# MCU_R5FSS0_CORE0 register map
Vendor: Texas Instruments
Peripheral module from a debugger description file (folder J7ES).
Registers are 32-bit, read-write, reset 0x0 unless marked. A register's access mark holds for its fields unless they carry their own. Offsets are as the file gives them; lines under a group give offsets from that group; [hi:lo] are bit positions; {n}, {i} and the like mark numbered series; 'fields as' and 'values as' point back to an identical list; <NAME> marks a mode.

## MCU_R5FSS0_CORE0
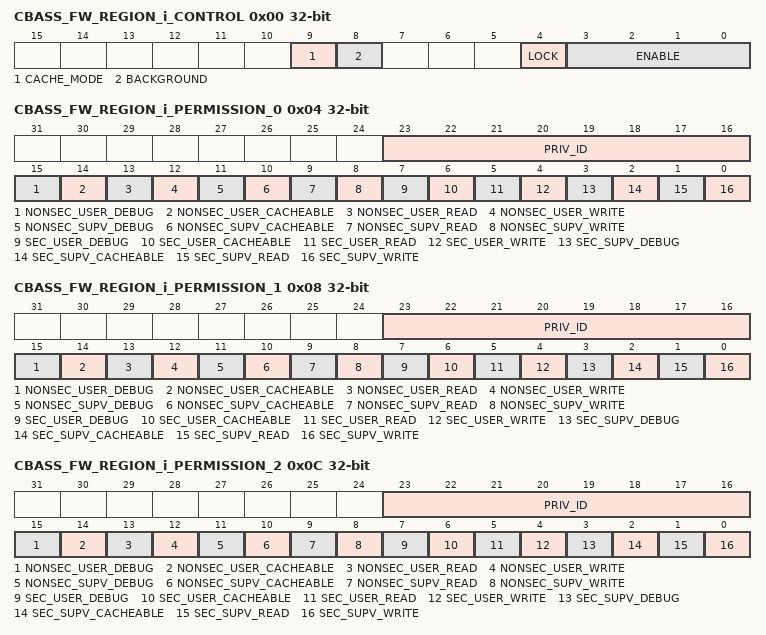
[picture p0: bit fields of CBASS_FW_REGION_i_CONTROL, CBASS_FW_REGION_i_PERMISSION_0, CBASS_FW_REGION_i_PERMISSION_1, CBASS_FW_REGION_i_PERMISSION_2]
0x00 CBASS_FW_REGION_i_CONTROL access not given — The Firewall Region i Control Register defines the control fields for the slave module (see ) region i firewall. Offset = 0h + (i * 20h). See column 'Firewall Regions' in through for the 'i' values associated with each slave.
  [9] CACHE_MODE rw — Cache mode for region.Set to 1 to check cache permissions.Set to 0 to ignore cache permissions.
  [8] BACKGROUND rw — Background enable for region.There can be one background region per firewall and foreground regions can have overlapping addresses only with the background region.
  [4] LOCK — Lock region.Once set region values cannot be modified. (access RW1S)
  [3:0] ENABLE rw — Enable region.A value of 0xA enables, others disable.
0x04 CBASS_FW_REGION_i_PERMISSION_0 — The Firewall Region i Permission 0 Register defines the permissions for the slave module (see ) region i firewall. Offset = 4h + (i * 20h). See column 'Firewall Regions' in through for the 'i' values associated with each slave.
  [23:16] PRIV_ID — Allowed privid.
  [15] NONSEC_USER_DEBUG — Non-secure user debug allowed.
  [14] NONSEC_USER_CACHEABLE — Non-secure user cacheable allowed.
  [13] NONSEC_USER_READ — Non-secure user read allowed.
  [12] NONSEC_USER_WRITE — Non-secure user write allowed.
  [11] NONSEC_SUPV_DEBUG — Non-secure supervisor debug allowed.
  [10] NONSEC_SUPV_CACHEABLE — Non-secure supervisor cacheable allowed.
  [9] NONSEC_SUPV_READ — Non-secure supervisor read allowed.
  [8] NONSEC_SUPV_WRITE — Non-secure supervisor write allowed.
  [7] SEC_USER_DEBUG — Secure user debug allowed.
  [6] SEC_USER_CACHEABLE — Secure user cacheable allowed.
  [5] SEC_USER_READ — Secure user read allowed.
  [4] SEC_USER_WRITE — Secure user write allowed.
  [3] SEC_SUPV_DEBUG — Secure supervisor debug allowed.
  [2] SEC_SUPV_CACHEABLE — Secure supervisor cacheable allowed.
  [1] SEC_SUPV_READ — Secure supervisor read allowed.
  [0] SEC_SUPV_WRITE — Secure supervisor write allowed.
0x08 CBASS_FW_REGION_i_PERMISSION_1 — The Firewall Region i Permission 1 Register defines the permissions for the slave module (see ) region i firewall. Offset = 8h + (i * 20h). See column 'Firewall Regions' in through for the 'i' values associated with each slave.
  fields as CBASS_FW_REGION_i_PERMISSION_0
0x0C CBASS_FW_REGION_i_PERMISSION_2 — The Firewall Region i Permission 2 Register defines the permissions for the module (see ) region i firewall. Offset = Ch + (i * 20h). See column 'Firewall Regions' in through for the 'i' values associated with each slave.
  fields as CBASS_FW_REGION_i_PERMISSION_0
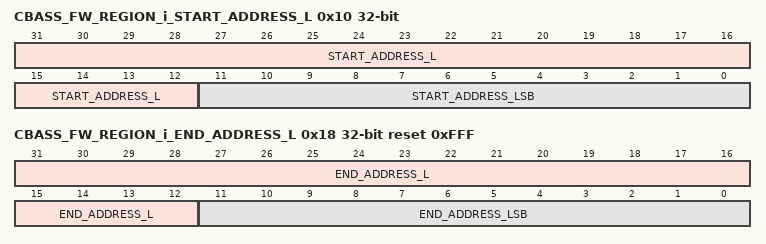
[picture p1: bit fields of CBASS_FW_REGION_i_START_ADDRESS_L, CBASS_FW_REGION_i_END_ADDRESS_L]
0x10 CBASS_FW_REGION_i_START_ADDRESS_L access per field (reset mask 0xFFF) — The Firewall Region i Start Address Low Register defines the start address bits 31 to 0 for the slave module (see ) region i firewall. Offset = 10h + (i * 20h). See column 'Firewall Regions' in through for the 'i' values associated with each slave.
  [31:12] START_ADDRESS_L rw — Start address bits 31 to 12.Lowest 12 bits are forced to 0 as address must be 4KB aligned.
  [11:0] START_ADDRESS_LSB ro — Start address bits 11 to 0 are forced to 0 as address must be 4KB aligned.
0x14 CBASS_FW_REGION_i_START_ADDRESS_H — The Firewall Region i Start Address High Register defines the start address bits 47 to 32 for the slave module (see ) region i firewall. Offset = 14h + (i * 20h). See column 'Firewall Regions' in through for the 'i' values associated with each slave.
  [15:0] START_ADDRESS_H — Start address bits 47 to 32.
0x18 CBASS_FW_REGION_i_END_ADDRESS_L access per field reset 0xFFF (reset mask 0xFFF) — The Firewall Region i End Address Low Register defines the end address bits 31 to 0 to include for the slave module (see ) region i firewall. Offset = 18h + (i * 20h). See column 'Firewall Regions' in through for the 'i' values associated with each slave.
  [31:12] END_ADDRESS_L rw — End address bits 31 to 12 to include in the match.Lowest 12 bits are forced to 1s as address must be 4KB aligned.
  [11:0] END_ADDRESS_LSB ro — End address bits 11 to 0 are forced to 1s as address must be 4KB aligned minus 1.
0x1C CBASS_FW_REGION_i_END_ADDRESS_H — The Firewall Region i End Address High Register defines the end address bits 47 to 32 to include for the slave module (see ) region i firewall. Offset = 1Ch + (i * 20h). See column 'Firewall Regions' in through for the 'i' values associated with each slave.
  [15:0] END_ADDRESS_H — End address bits 47 to 32 to include in the match.
